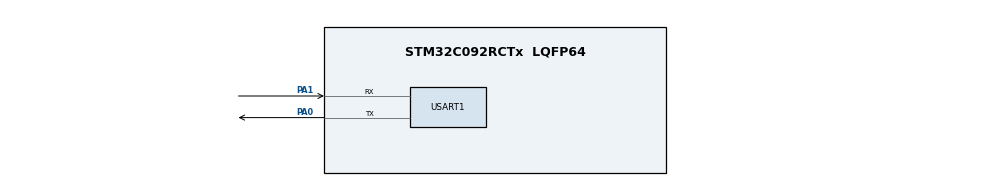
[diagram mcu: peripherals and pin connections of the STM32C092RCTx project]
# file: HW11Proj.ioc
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Mcu.Family=STM32C0
Mcu.Name=STM32C092RCTx
Mcu.Package=LQFP64
NUCLEO-C092RC.BUTTON=1
NUCLEO-C092RC.Bsp_Common_DEMO=true
NUCLEO-C092RC.LD1=true
NUCLEO-C092RC.LD2=true
NUCLEO-C092RC.VCP=true
NVIC.EXTI4_15_IRQn=true\:0\:0\:false\:false\:true\:false\:true\:true
PA0.Mode=Asynchronous
PA0.Signal=USART1_TX
PA1.Mode=Asynchronous
PA1.Signal=USART1_RX
PA13.GPIO_Label=SWDIO
PA13.Signal=DEBUG_SWDIO
PA14-BOOT0.GPIO_Label=SWCLK
PA14-BOOT0.Signal=DEBUG_SWCLK
PA2.Signal=USART2_TX
PA3.Signal=USART2_RX
PC14-OSCX_IN(PC14).GPIO_Label=OSCX_IN
PC14-OSCX_IN(PC14).Signal=RCC_OSCX_IN
PC15-OSCX_OUT(PC15).GPIO_Label=OSCX_OUT
PC15-OSCX_OUT(PC15).Signal=RCC_OSCX_OUT
PF0-OSC_IN(PF0).GPIO_Label=OSC_IN
PF0-OSC_IN(PF0).Signal=RCC_OSC_IN
PF1-OSC_OUT(PF1).GPIO_Label=OSC_OUT
PF1-OSC_OUT(PF1).Signal=RCC_OSC_OUT
ProjectManager.HeapSize=0x200
ProjectManager.StackSize=0x400
ProjectManager.TargetToolchain=STM32CubeIDE
RCC.ADCFreq_Value=12000000
RCC.AHBFreq_Value=12000000
RCC.CortexFreq_Value=12000000
RCC.EXTERNAL_CLOCK_VALUE=12288000
RCC.HCLKFreq_Value=12000000
RCC.HSE_VALUE=8000000
RCC.HSI_VALUE=48000000
RCC.LSE_VALUE=32768
RCC.SYSCLKFreq_VALUE=12000000
USART1.VirtualMode-Asynchronous=VM_ASYNC
VP_NUCLEO-C092RC_VS_BSP_COMMON.Mode=COMMON
board=NUCLEO-C092RC

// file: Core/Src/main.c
/* USER CODE BEGIN Header */
/**
  ******************************************************************************
  * @file           : main.c
  * @brief          : Main program body
  ******************************************************************************
  * @attention
  *
  * Copyright (c) 2026 STMicroelectronics.
  * All rights reserved.
  *
  * This software is licensed under terms that can be found in the LICENSE file
  * in the root directory of this software component.
  * If no LICENSE file comes with this software, it is provided AS-IS.
  *
  ******************************************************************************
  */
/* USER CODE END Header */
#include "main.h"

/* USER CODE BEGIN Includes */

#include "string.h"
#include "stdio.h"
/* USER CODE END Includes */

COM_InitTypeDef BspCOMInit;
__IO uint32_t BspButtonState = BUTTON_RELEASED;

UART_HandleTypeDef huart1;

void SystemClock_Config(void);
static void MX_GPIO_Init(void);
static void MX_USART1_UART_Init(void);

int main(void)
{

  /* MCU Configuration--------------------------------------------------------*/

  /* Reset of all peripherals, Initializes the Flash interface and the Systick. */
  HAL_Init();

  /* Configure the system clock */
  SystemClock_Config();

  /* Initialize all configured peripherals */
  MX_GPIO_Init();
  MX_USART1_UART_Init();

  /* Initialize leds */
  BSP_LED_Init(LED_GREEN);
  BSP_LED_Init(LED_BLUE);

  /* Initialize USER push-button, will be used to trigger an interrupt each time it's pressed.*/
  BSP_PB_Init(BUTTON_USER, BUTTON_MODE_EXTI);

  /* Initialize COM1 port (115200, 8 bits (7-bit data + 1 stop bit), no parity */
  BspCOMInit.BaudRate   = 115200;
  BspCOMInit.WordLength = COM_WORDLENGTH_8B;
  BspCOMInit.StopBits   = COM_STOPBITS_1;
  BspCOMInit.Parity     = COM_PARITY_NONE;
  BspCOMInit.HwFlowCtl  = COM_HWCONTROL_NONE;
  if (BSP_COM_Init(COM1, &BspCOMInit) != BSP_ERROR_NONE)
  {
    Error_Handler();
  }

  /* USER CODE BEGIN BSP */

  /* -- Sample board code to send message over COM1 port ---- */
  printf("Welcome to STM32 world !\n\r");

  /* -- Sample board code to switch on leds ---- */
  BSP_LED_On(LED_GREEN);
  BSP_LED_On(LED_BLUE);

  /* USER CODE END BSP */

  /* Infinite loop */
  /* USER CODE BEGIN WHILE */
  while (1)
  {

    /* -- Sample board code for User push-button in interrupt mode ---- */
    if (BspButtonState == BUTTON_PRESSED)
    {
      /* Update button state */
      BspButtonState = BUTTON_RELEASED;
      /* -- Sample board code to toggle leds ---- */
      BSP_LED_Toggle(LED_GREEN);
      BSP_LED_Toggle(LED_BLUE);
      printf("hello\r\n");

      char m[100];
      int number = 5;
      sprintf(m, "hello %d\r\n", number);
      HAL_UART_Transmit(&huart1, (uint8_t *)m, strlen(m), 10);

      int rxNumber;

      char rxMessage[100];
      char buffer[1000];
      int index = 0;

      HAL_UART_Receive(&huart1, (uint8_t *)rxMessage, strlen(rxMessage), 10);
      // 99 leaves room for null terminator

      for (int i = 0; strlen(rxMessage); i++) {
          if (rxMessage[i] == '\n') {
//              buffer[index] = '\0';
              sscanf(buffer, "%d", &rxNumber);
              printf("Received number: %d\r\n", rxNumber);
              index = 0;
          } else {
              buffer[index] = rxMessage[i];
              index++;
              if (index >= 999) {
                  index = 0;
              }
          }
      }

    }

      /* ..... Perform your action ..... */
    }
    /* USER CODE END WHILE */

  }

void SystemClock_Config(void)
{
  RCC_OscInitTypeDef RCC_OscInitStruct = {0};
  RCC_ClkInitTypeDef RCC_ClkInitStruct = {0};

  __HAL_FLASH_SET_LATENCY(FLASH_LATENCY_0);

  /** Initializes the RCC Oscillators according to the specified parameters
  * in the RCC_OscInitTypeDef structure.
  */
  RCC_OscInitStruct.OscillatorType = RCC_OSCILLATORTYPE_HSI;
  RCC_OscInitStruct.HSIState = RCC_HSI_ON;
  RCC_OscInitStruct.HSIDiv = RCC_HSI_DIV4;
  RCC_OscInitStruct.HSICalibrationValue = RCC_HSICALIBRATION_DEFAULT;
  if (HAL_RCC_OscConfig(&RCC_OscInitStruct) != HAL_OK)
  {
    Error_Handler();
  }

  /** Initializes the CPU, AHB and APB buses clocks
  */
  RCC_ClkInitStruct.ClockType = RCC_CLOCKTYPE_HCLK|RCC_CLOCKTYPE_SYSCLK
                              |RCC_CLOCKTYPE_PCLK1;
  RCC_ClkInitStruct.SYSCLKSource = RCC_SYSCLKSOURCE_HSI;
  RCC_ClkInitStruct.SYSCLKDivider = RCC_SYSCLK_DIV1;
  RCC_ClkInitStruct.AHBCLKDivider = RCC_HCLK_DIV1;
  RCC_ClkInitStruct.APB1CLKDivider = RCC_APB1_DIV1;

  if (HAL_RCC_ClockConfig(&RCC_ClkInitStruct, FLASH_LATENCY_0) != HAL_OK)
  {
    Error_Handler();
  }
}

static void MX_USART1_UART_Init(void)
{

  huart1.Instance = USART1;
  huart1.Init.BaudRate = 115200;
  huart1.Init.WordLength = UART_WORDLENGTH_8B;
  huart1.Init.StopBits = UART_STOPBITS_1;
  huart1.Init.Parity = UART_PARITY_NONE;
  huart1.Init.Mode = UART_MODE_TX_RX;
  huart1.Init.HwFlowCtl = UART_HWCONTROL_NONE;
  huart1.Init.OverSampling = UART_OVERSAMPLING_16;
  huart1.Init.OneBitSampling = UART_ONE_BIT_SAMPLE_DISABLE;
  huart1.Init.ClockPrescaler = UART_PRESCALER_DIV1;
  huart1.AdvancedInit.AdvFeatureInit = UART_ADVFEATURE_NO_INIT;
  if (HAL_UART_Init(&huart1) != HAL_OK)
  {
    Error_Handler();
  }
  if (HAL_UARTEx_SetTxFifoThreshold(&huart1, UART_TXFIFO_THRESHOLD_1_8) != HAL_OK)
  {
    Error_Handler();
  }
  if (HAL_UARTEx_SetRxFifoThreshold(&huart1, UART_RXFIFO_THRESHOLD_1_8) != HAL_OK)
  {
    Error_Handler();
  }
  if (HAL_UARTEx_DisableFifoMode(&huart1) != HAL_OK)
  {
    Error_Handler();
  }

}

static void MX_GPIO_Init(void)
{

  /* GPIO Ports Clock Enable */
  __HAL_RCC_GPIOC_CLK_ENABLE();
  __HAL_RCC_GPIOF_CLK_ENABLE();
  __HAL_RCC_GPIOA_CLK_ENABLE();

}

/**
  * @brief  BSP Push Button callback
  * @param  Button Specifies the pressed button
  * @retval None
  */
void BSP_PB_Callback(Button_TypeDef Button)
{
  if (Button == BUTTON_USER)
  {
    BspButtonState = BUTTON_PRESSED;
  }
}

void Error_Handler(void)
{
  __disable_irq();
  while (1)
  {
  }
}
